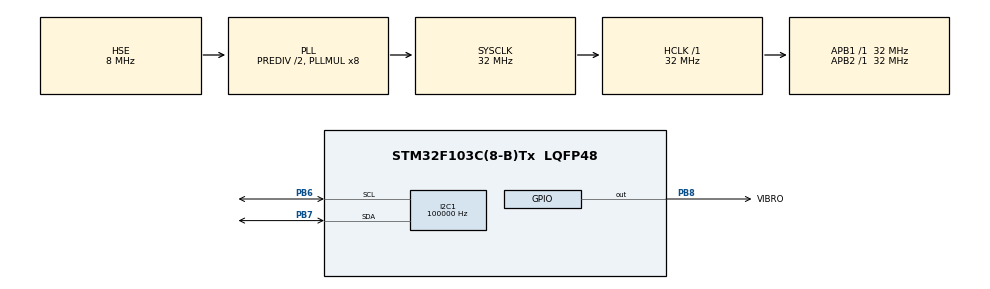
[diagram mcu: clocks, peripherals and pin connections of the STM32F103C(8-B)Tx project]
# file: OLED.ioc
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I2C1.ClockSpeed=100000
I2C1.I2C_Mode=I2C_Standard
Mcu.Family=STM32F1
Mcu.Name=STM32F103C(8-B)Tx
Mcu.Package=LQFP48
NVIC.PriorityGroup=NVIC_PRIORITYGROUP_4
NVIC.RTC_IRQn=true\:0\:0\:false\:false\:true\:true
PA13.Mode=Serial_Wire
PA13.Signal=SYS_JTMS-SWDIO
PA14.Mode=Serial_Wire
PA14.Signal=SYS_JTCK-SWCLK
PB6.Mode=I2C
PB6.Signal=I2C1_SCL
PB7.Mode=I2C
PB7.Signal=I2C1_SDA
PB8.GPIO_Label=VIBRO
PB8.Signal=GPIO_Output
PC14-OSC32_IN.Mode=LSE-External-Oscillator
PC14-OSC32_IN.Signal=RCC_OSC32_IN
PC15-OSC32_OUT.Mode=LSE-External-Oscillator
PC15-OSC32_OUT.Signal=RCC_OSC32_OUT
PD0-OSC_IN.Mode=HSE-External-Oscillator
PD0-OSC_IN.Signal=RCC_OSC_IN
PD1-OSC_OUT.Mode=HSE-External-Oscillator
PD1-OSC_OUT.Signal=RCC_OSC_OUT
ProjectManager.HeapSize=0x200
ProjectManager.StackSize=0x400
ProjectManager.TargetToolchain=TrueSTUDIO
RCC.ADCPresc=RCC_ADCPCLK2_DIV4
RCC.AHBFreq_Value=32000000
RCC.APB1Freq_Value=32000000
RCC.APB1TimFreq_Value=32000000
RCC.APB2Freq_Value=32000000
RCC.APB2TimFreq_Value=32000000
RCC.HCLKFreq_Value=32000000
RCC.HSEDivPLL=RCC_HSE_PREDIV_DIV2
RCC.PLLMUL=RCC_PLL_MUL8
RCC.PLLSourceVirtual=RCC_PLLSOURCE_HSE
RCC.RTCClockSelection=RCC_RTCCLKSOURCE_LSE
RCC.SYSCLKFreq_VALUE=32000000
RCC.SYSCLKSource=RCC_SYSCLKSOURCE_PLLCLK
RCC.USBFreq_Value=32000000
RTC.Date=16
RTC.Hours=11
RTC.Minutes=10
RTC.Seconds=50
RTC.WeekDay=RTC_WEEKDAY_TUESDAY
RTC.Year=18
VP_RTC_VS_RTC_Activate.Mode=RTC_Enabled
VP_RTC_VS_RTC_Calendar.Mode=RTC_Calendar
board=OLED

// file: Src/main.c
/**
  ******************************************************************************
  * File Name          : main.c
  * Description        : Main program body
  ******************************************************************************
  ** This notice applies to any and all portions of this file
  * that are not between comment pairs USER CODE BEGIN and
  * USER CODE END. Other portions of this file, whether
  * inserted by the user or by software development tools
  * are owned by their respective copyright owners.
  *
  * COPYRIGHT(c) 2018 STMicroelectronics
  *
  * Redistribution and use in source and binary forms, with or without modification,
  * are permitted provided that the following conditions are met:
  *   1. Redistributions of source code must retain the above copyright notice,
  *      this list of conditions and the following disclaimer.
  *   2. Redistributions in binary form must reproduce the above copyright notice,
  *      this list of conditions and the following disclaimer in the documentation
  *      and/or other materials provided with the distribution.
  *   3. Neither the name of STMicroelectronics nor the names of its contributors
  *      may be used to endorse or promote products derived from this software
  *      without specific prior written permission.
  *
  * THIS SOFTWARE IS PROVIDED BY THE COPYRIGHT HOLDERS AND CONTRIBUTORS "AS IS"
  * AND ANY EXPRESS OR IMPLIED WARRANTIES, INCLUDING, BUT NOT LIMITED TO, THE
  * IMPLIED WARRANTIES OF MERCHANTABILITY AND FITNESS FOR A PARTICULAR PURPOSE ARE
  * DISCLAIMED. IN NO EVENT SHALL THE COPYRIGHT HOLDER OR CONTRIBUTORS BE LIABLE
  * FOR ANY DIRECT, INDIRECT, INCIDENTAL, SPECIAL, EXEMPLARY, OR CONSEQUENTIAL
  * DAMAGES (INCLUDING, BUT NOT LIMITED TO, PROCUREMENT OF SUBSTITUTE GOODS OR
  * SERVICES; LOSS OF USE, DATA, OR PROFITS; OR BUSINESS INTERRUPTION) HOWEVER
  * CAUSED AND ON ANY THEORY OF LIABILITY, WHETHER IN CONTRACT, STRICT LIABILITY,
  * OR TORT (INCLUDING NEGLIGENCE OR OTHERWISE) ARISING IN ANY WAY OUT OF THE USE
  * OF THIS SOFTWARE, EVEN IF ADVISED OF THE POSSIBILITY OF SUCH DAMAGE.
  *
  ******************************************************************************
  */

#include "main.h"
#include "stm32f1xx_hal.h"
#include "i2c.h"
#include "rtc.h"
#include "gpio.h"

/* USER CODE BEGIN Includes */
#include  "SSD1306.h"
#include "pictures.h"

#include "CorperBlack.h" //TESTED-OK.
#include "CoorperNew.h"	  //TESTED-OK.
#include "Impact_12pt.h" //TESTED-OK
#include "Impact_22pt.h" //TESTED-OK
/* USER CODE END Includes */

/* USER CODE BEGIN PV */
/* Private variables ---------------------------------------------------------*/
RTC_TimeTypeDef timeSet = { 11, 40, 57 };
RTC_DateTypeDef dateSet = { RTC_WEEKDAY_WEDNESDAY, RTC_MONTH_JANUARY, 16, 18 };

RTC_TimeTypeDef timeToDisplay;
RTC_DateTypeDef dateToDisplay;
/* USER CODE END PV */

void SystemClock_Config(void);

/* USER CODE BEGIN PFP */
/* Private function prototypes -----------------------------------------------*/
void
simpleDisplayDemo (void);
/* USER CODE END PFP */

int main(void)
{

  /* MCU Configuration----------------------------------------------------------*/

  /* Reset of all peripherals, Initializes the Flash interface and the Systick. */
  HAL_Init();

  /* Configure the system clock */
  SystemClock_Config();

  /* USER CODE BEGIN SysInit */
    __HAL_RCC_I2C1_CLK_ENABLE()
    ;
    __HAL_RCC_I2C1_FORCE_RESET();
    __HAL_RCC_I2C1_RELEASE_RESET();
  /* USER CODE END SysInit */

  /* Initialize all configured peripherals */
  MX_GPIO_Init();
  MX_I2C1_Init();
  MX_RTC_Init();

  /* USER CODE BEGIN 2 */
    ssd1306_initDisplay ();

    //simpleDisplayDemo ();

  /* USER CODE END 2 */

  /* Infinite loop */
  /* USER CODE BEGIN WHILE */
    ssd1306_putString("Hello",&impact_22ptFontInfo,SSD1306_BLACK);
    ssd1306_putString("Hello",&impact_12ptFontInfo,SSD1306_BLACK);
    ssd1306_updateScreen();

    while (1)
    {
  /* USER CODE END WHILE */

    }

}

/** System Clock Configuration
*/
void SystemClock_Config(void)
{

  RCC_OscInitTypeDef RCC_OscInitStruct;
  RCC_ClkInitTypeDef RCC_ClkInitStruct;
  RCC_PeriphCLKInitTypeDef PeriphClkInit;

    /**Initializes the CPU, AHB and APB busses clocks
    */
  RCC_OscInitStruct.OscillatorType = RCC_OSCILLATORTYPE_HSE|RCC_OSCILLATORTYPE_LSE;
  RCC_OscInitStruct.HSEState = RCC_HSE_ON;
  RCC_OscInitStruct.HSEPredivValue = RCC_HSE_PREDIV_DIV2;
  RCC_OscInitStruct.LSEState = RCC_LSE_ON;
  RCC_OscInitStruct.HSIState = RCC_HSI_ON;
  RCC_OscInitStruct.PLL.PLLState = RCC_PLL_ON;
  RCC_OscInitStruct.PLL.PLLSource = RCC_PLLSOURCE_HSE;
  RCC_OscInitStruct.PLL.PLLMUL = RCC_PLL_MUL8;
  if (HAL_RCC_OscConfig(&RCC_OscInitStruct) != HAL_OK)
  {
    _Error_Handler(__FILE__, __LINE__);
  }

    /**Initializes the CPU, AHB and APB busses clocks
    */
  RCC_ClkInitStruct.ClockType = RCC_CLOCKTYPE_HCLK|RCC_CLOCKTYPE_SYSCLK
                              |RCC_CLOCKTYPE_PCLK1|RCC_CLOCKTYPE_PCLK2;
  RCC_ClkInitStruct.SYSCLKSource = RCC_SYSCLKSOURCE_PLLCLK;
  RCC_ClkInitStruct.AHBCLKDivider = RCC_SYSCLK_DIV1;
  RCC_ClkInitStruct.APB1CLKDivider = RCC_HCLK_DIV1;
  RCC_ClkInitStruct.APB2CLKDivider = RCC_HCLK_DIV1;

  if (HAL_RCC_ClockConfig(&RCC_ClkInitStruct, FLASH_LATENCY_1) != HAL_OK)
  {
    _Error_Handler(__FILE__, __LINE__);
  }

  PeriphClkInit.PeriphClockSelection = RCC_PERIPHCLK_RTC;
  PeriphClkInit.RTCClockSelection = RCC_RTCCLKSOURCE_LSE;
  if (HAL_RCCEx_PeriphCLKConfig(&PeriphClkInit) != HAL_OK)
  {
    _Error_Handler(__FILE__, __LINE__);
  }

    /**Configure the Systick interrupt time
    */
  HAL_SYSTICK_Config(HAL_RCC_GetHCLKFreq()/1000);

    /**Configure the Systick
    */
  HAL_SYSTICK_CLKSourceConfig(SYSTICK_CLKSOURCE_HCLK);

  /* SysTick_IRQn interrupt configuration */
  HAL_NVIC_SetPriority(SysTick_IRQn, 0, 0);
}

/* USER CODE BEGIN 4 */

void
simpleDisplayDemo (void)
{

    for (int i = 53; i < 68; i++)
    {
        ssd1306_putChar (i, &cooperBlack_8ptFontInfo, SSD1306_WHITE);
    }

    for (int i = 53; i < 68; i++)
    {
        ssd1306_putChar (i, &impact_12ptFontInfo, SSD1306_WHITE);
    }
    for (int i = 52; i < 55; i++)
    {
        ssd1306_putChar (i, &impact_22ptFontInfo, SSD1306_WHITE);
    }
    ssd1306_drawRectangle (10, 10, 20, 20, SSD1306_WHITE);
    ssd1306_drawRectangle (20, 20, 120, 40, SSD1306_WHITE);
    ssd1306_drawCircle (20, 20, 10, SSD1306_WHITE);
    ssd1306_drawCircle (65, 32, 15, SSD1306_WHITE);
    ssd1306_drawLine (0, 0, 128, 64, SSD1306_WHITE);
    ssd1306_drawLine (0, 64, 128, 0, SSD1306_WHITE);
    ssd1306_drawLine (0, 32, 128, 32, SSD1306_WHITE);
    ssd1306_updateScreen ();
    HAL_Delay (2000);

    ssd1306_fill(SSD1306_BLACK);
    ssd1306_updateScreen ();
    HAL_Delay (2000);

    ssd1306_fill(SSD1306_WHITE);
    ssd1306_updateScreen ();
    HAL_Delay (2000);

    ssd1306_putString ("Test display rotation", &cooperBlack_8ptFontInfo, SSD1306_WHITE);
    ssd1306_updateScreen ();

    ssd1306_makeShortScroll (rightHorizontal, frames_2, 0x00, 0x0F);
    HAL_Delay (2000);
    ssd1306_makeShortScroll (leftHorizontal, frames_5, 0x00, 0x02);
    ssd1306_makeShortScroll (rightHorizontal, frames_5, 0x01, 0x02);
    HAL_Delay (2000);
    ssd1306_deActivateScroll ();

    ssd1306_fill(SSD1306_BLACK);
    ssd1306_updateScreen ();

    ssd1306_putString("/dev/drugs/C++", &cooperBlack_8ptFontInfo, SSD1306_WHITE );
    ssd1306_setCursor(0,11);
    ssd1306_putString("Hello World!", &cooperBlack_8ptFontInfo, SSD1306_WHITE );
    ssd1306_setCursor(0,22);
    ssd1306_putString("Test display ON/OFF", &cooperBlack_8ptFontInfo, SSD1306_WHITE );
    ssd1306_updateScreen ();
    HAL_Delay(1000);
    ssd1306_displayOff();
    HAL_Delay(1000);
    ssd1306_displayOn();
}
/* USER CODE END 4 */

void _Error_Handler(char * file, int line)
{
    while (1)
    {
    }
}

/************************ (C) COPYRIGHT STMicroelectronics *****END OF FILE****/
